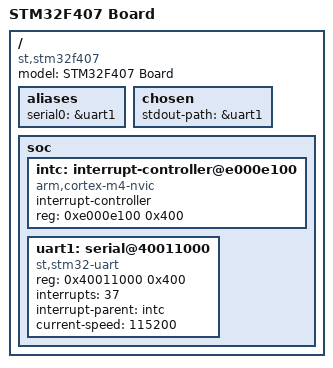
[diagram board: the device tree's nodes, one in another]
/dts-v1/;

/ {
    model = "STM32F407 Board";
    compatible = "st,stm32f407";

    aliases {
        serial0 = &uart1;
    };

    chosen {
        stdout-path = &uart1;
    };

    soc {
        #address-cells = <1>;
        #size-cells = <1>;

        intc: interrupt-controller@e000e100 {
            compatible = "arm,cortex-m4-nvic";
            interrupt-controller;
            #interrupt-cells = <1>;
            reg = <0xe000e100 0x400>;
        };

        uart1: serial@40011000 {
            compatible = "st,stm32-uart";
            reg = <0x40011000 0x400>;
            interrupts = <37>;
            interrupt-parent = <&intc>;  
            current-speed = <115200>;
            status = "okay";
        };
    };
};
